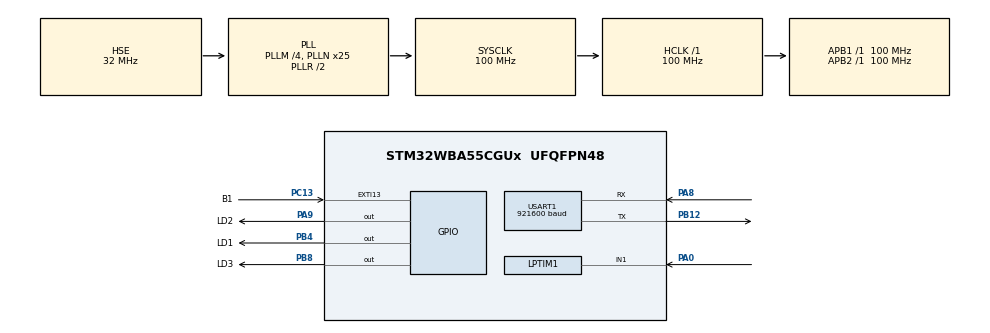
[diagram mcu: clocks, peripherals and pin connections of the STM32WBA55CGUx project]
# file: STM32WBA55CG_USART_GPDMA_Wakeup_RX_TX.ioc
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CORTEX_M33_NS.userName=CORTEX_M33
GPDMA1.CIRCULARMODE_GPDMACH2=ENABLE
GPDMA1.DESTINC_GPDMACH2=DMA_DINC_INCREMENTED
GPDMA1.DIRECTION_GPDMACH3=DMA_MEMORY_TO_PERIPH
GPDMA1.IPHANDLE_GPDMACH2-SIMPLEREQUEST_GPDMACH2=__NULL
GPDMA1.IPHANDLE_GPDMACH3-SIMPLEREQUEST_GPDMACH3=__NULL
GPDMA1.PRIORITY_GPDMACH3=DMA_LOW_PRIORITY_HIGH_WEIGHT
GPDMA1.REQUEST_GPDMACH2=GPDMA1_REQUEST_USART1_RX
GPDMA1.REQUEST_GPDMACH3=GPDMA1_REQUEST_USART1_TX
GPDMA1.SRCINC_GPDMACH3=DMA_SINC_INCREMENTED
LPTIM1.Period=1000
LPTIM1.TriggerSource=LPTIM_TRIGSOURCE_SOFTWARE
LPTIM1.ULPClockPolarity=LPTIM_CLOCKPOLARITY_RISING
LPTIM1.ULPClockSampleTime=LPTIM_CLOCKSAMPLETIME_DIRECTTRANSITION
LPTIM1.UpdateMode=LPTIM_UPDATE_IMMEDIATE
Mcu.Family=STM32WBA
Mcu.Name=STM32WBA55CGUx
Mcu.Package=UFQFPN48
NVIC.EXTI13_IRQn=true\:0\:0\:false\:false\:true\:true\:true\:true
NVIC.GPDMA1_Channel2_IRQn=true\:0\:0\:false\:false\:true\:false\:true\:true
NVIC.GPDMA1_Channel3_IRQn=true\:0\:0\:false\:false\:true\:false\:true\:true
NVIC.LPTIM1_IRQn=true\:0\:0\:false\:false\:true\:true\:true\:true
NVIC.PriorityGroup=NVIC_PRIORITYGROUP_4
OSC_IN.Mode=HSE-External-Oscillator
OSC_IN.Signal=RCC_OSC_IN
OSC_OUT.Mode=HSE-External-Oscillator
OSC_OUT.Signal=RCC_OSC_OUT
PA0.Mode=Counts_external_clock_with_synchro_01_occur1
PA0.Signal=LPTIM1_IN1
PA8.Mode=Asynchronous
PA8.Signal=USART1_RX
PA9.GPIO_Label=LD2
PA9.Signal=GPIO_Output
PB12.Mode=Asynchronous
PB12.Signal=USART1_TX
PB4\ (NJTRST).GPIO_Label=LD1
PB4\ (NJTRST).Signal=GPIO_Output
PB8.GPIO_Label=LD3
PB8.Signal=GPIO_Output
PC13.GPIO_Label=B1
PC13.GPIO_ModeDefaultEXTI=GPIO_MODE_IT_FALLING
PC13.GPIO_PuPd=GPIO_PULLUP
PC13.Signal=GPXTI13
ProjectManager.HeapSize=0x200
ProjectManager.StackSize=0x400
ProjectManager.TargetToolchain=STM32CubeIDE
RCC.ADCFreq_Value=100000000
RCC.AHB5CLKDivider=DIV4
RCC.AHBFreq_Value=100000000
RCC.APB1Freq_Value=100000000
RCC.APB1TimFreq_Value=100000000
RCC.APB2Freq_Value=100000000
RCC.APB2TimFreq_Value=100000000
RCC.CortexFreq_Value=12500000
RCC.HCLKFreq_Value=100000000
RCC.HSE_VALUE=32000000
RCC.HSI_VALUE=16000000
RCC.LPTIM1CLockSelectionVirtual=RCC_LPTIM1CLKSOURCE_LSI
RCC.LSE_VALUE=32768
RCC.LSI1_VALUE=32000
RCC.LSI2_VALUE=32000
RCC.PLLFRACN=0
RCC.PLLM=4
RCC.PLLN=25
RCC.PLLSourceVirtual=RCC_PLLSOURCE_HSE
RCC.SYSCLKFreq_VALUE=100000000
RCC.SYSCLKSourceVirtual=RCC_SYSCLKSOURCE_PLLCLK
RCC.SupplySource=PWR_SMPS_SUPPLY
RCC.USART1CLockSelectionVirtual=RCC_USART1CLKSOURCE_HSI
RCC.VCOOutputFreq_Value=200000000
USART1.AutonomousMode=AUTONOMOUS_MODE_ENABLE
USART1.BaudRate=921600
USART1.DataSize=10
USART1.IdleFrame=UART_IDLE_FRAME_ENABLE
USART1.TriggerSelection=UART_LPTIM1_OUT_TRG
USART1.VirtualMode-Asynchronous=VM_ASYNC
VP_CORTEX_M33_NS_VS_Hclk.Mode=Hclk_Mode
VP_GPDMA1_VS_GPDMACH2.Mode=SIMPLEREQUEST_GPDMACH2
VP_GPDMA1_VS_GPDMACH3.Mode=SIMPLEREQUEST_GPDMACH3
VP_ICACHE_VS_ICACHE.Mode=DirectMappedCache
VP_MEMORYMAP_VS_MEMORYMAP.Mode=CurAppReg
VP_PWR_VS_SECSignals.Mode=Security/Privilege
board=custom

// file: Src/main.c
/* USER CODE BEGIN Header */
/**
  ******************************************************************************
  * @file    LPTIM/LPTIM_PulseCounter/Src/main.c
  * @author  MCD Application Team
  * @brief   This example describes how to configure and use the LPTIM in counter
  *          mode through the STM32WBAxx HAL API.
  ******************************************************************************
  * @attention
  *
  * Copyright (c) 2022 STMicroelectronics.
  * All rights reserved.
  *
  * This software is licensed under terms that can be found in the LICENSE file
  * in the root directory of this software component.
  * If no LICENSE file comes with this software, it is provided AS-IS.
  *
  ******************************************************************************
  */
/* USER CODE END Header */
#include "main.h"

LPTIM_HandleTypeDef hlptim1;

UART_HandleTypeDef huart1;
DMA_HandleTypeDef handle_GPDMA1_Channel3;
DMA_NodeTypeDef Node_GPDMA1_Channel2;
DMA_QListTypeDef List_GPDMA1_Channel2;
DMA_HandleTypeDef handle_GPDMA1_Channel2;

void SystemClock_Config(void);
static void MX_GPIO_Init(void);
static void MX_GPDMA1_Init(void);
static void MX_ICACHE_Init(void);
static void MX_USART1_UART_Init(void);
static void MX_LPTIM1_Init(void);

int main(void)
{

  /* USER CODE BEGIN 1 */
  /* STM32WBAxx HAL library initialization:
       - Systick timer is configured by default as source of time base, but user
             can eventually implement his proper time base source (a general purpose
             timer for example or other time source), keeping in mind that Time base
             duration should be kept 1ms since PPP_TIMEOUT_VALUEs are defined and
             handled in milliseconds basis.
       - Set NVIC Group Priority to 4
       - Low Level Initialization
     */

  /* USER CODE END 1 */

  /* MCU Configuration--------------------------------------------------------*/

  /* Reset of all peripherals, Initializes the Flash interface and the Systick. */
  HAL_Init();

  /* Configure the system clock */
  SystemClock_Config();

  /* Initialize all configured peripherals */
  MX_GPIO_Init();
  MX_GPDMA1_Init();
  MX_ICACHE_Init();
  MX_USART1_UART_Init();
  MX_LPTIM1_Init();
  /* USER CODE BEGIN 2 */

  /* ### Start counting in interrupt mode ############################# */
  /*
   *  Period = 1000
   */
  if (HAL_LPTIM_Counter_Start_IT(&hlptim1) != HAL_OK)
  {
    Error_Handler();
  }

  /* Disable autoreload write complete interrupt */
  __HAL_LPTIM_DISABLE_IT(&hlptim1, LPTIM_IT_ARROK);

  /* ### Enter in Stop mode ########################################### */
  HAL_PWR_EnterSTOPMode(PWR_LOWPOWERREGULATOR_ON, PWR_STOPENTRY_WFI);

  /* USER CODE END 2 */

  /* Infinite loop */
  while (1)
  {

  }
}

void SystemClock_Config(void)
{
  RCC_OscInitTypeDef RCC_OscInitStruct = {0};
  RCC_ClkInitTypeDef RCC_ClkInitStruct = {0};

  /** Supply configuration update enable
  */
  HAL_PWREx_ConfigSupply(PWR_SMPS_SUPPLY);

  /** Configure the main internal regulator output voltage
  */
  if (HAL_PWREx_ControlVoltageScaling(PWR_REGULATOR_VOLTAGE_SCALE1) != HAL_OK)
  {
    Error_Handler();
  }

  /** Initializes the CPU, AHB and APB busses clocks
  */
  RCC_OscInitStruct.OscillatorType = RCC_OSCILLATORTYPE_HSI|RCC_OSCILLATORTYPE_LSI
                              |RCC_OSCILLATORTYPE_HSE;
  RCC_OscInitStruct.HSEState = RCC_HSE_ON;
  RCC_OscInitStruct.HSEDiv = RCC_HSE_DIV1;
  RCC_OscInitStruct.HSIState = RCC_HSI_ON;
  RCC_OscInitStruct.HSICalibrationValue = RCC_HSICALIBRATION_DEFAULT;
  RCC_OscInitStruct.LSIState = RCC_LSI1_ON;
  RCC_OscInitStruct.LSIDiv = RCC_LSI_DIV1;
  RCC_OscInitStruct.PLL1.PLLState = RCC_PLL_ON;
  RCC_OscInitStruct.PLL1.PLLSource = RCC_PLLSOURCE_HSE;
  RCC_OscInitStruct.PLL1.PLLM = 4;
  RCC_OscInitStruct.PLL1.PLLN = 25;
  RCC_OscInitStruct.PLL1.PLLP = 2;
  RCC_OscInitStruct.PLL1.PLLQ = 2;
  RCC_OscInitStruct.PLL1.PLLR = 2;
  RCC_OscInitStruct.PLL1.PLLFractional = 0;
  if (HAL_RCC_OscConfig(&RCC_OscInitStruct) != HAL_OK)
  {
    Error_Handler();
  }

  /** Initializes the CPU, AHB and APB busses clocks
  */
  RCC_ClkInitStruct.ClockType = RCC_CLOCKTYPE_HCLK|RCC_CLOCKTYPE_SYSCLK
                              |RCC_CLOCKTYPE_PCLK1|RCC_CLOCKTYPE_PCLK2
                              |RCC_CLOCKTYPE_PCLK7|RCC_CLOCKTYPE_HCLK5;
  RCC_ClkInitStruct.SYSCLKSource = RCC_SYSCLKSOURCE_PLLCLK;
  RCC_ClkInitStruct.AHBCLKDivider = RCC_SYSCLK_DIV1;
  RCC_ClkInitStruct.APB1CLKDivider = RCC_HCLK_DIV1;
  RCC_ClkInitStruct.APB2CLKDivider = RCC_HCLK_DIV1;
  RCC_ClkInitStruct.APB7CLKDivider = RCC_HCLK_DIV1;
  RCC_ClkInitStruct.AHB5_PLL1_CLKDivider = RCC_SYSCLK_PLL1_DIV4;
  RCC_ClkInitStruct.AHB5_HSEHSI_CLKDivider = RCC_SYSCLK_HSEHSI_DIV1;

  if (HAL_RCC_ClockConfig(&RCC_ClkInitStruct, FLASH_LATENCY_3) != HAL_OK)
  {
    Error_Handler();
  }
}

static void MX_GPDMA1_Init(void)
{

  /* Peripheral clock enable */
  __HAL_RCC_GPDMA1_CLK_ENABLE();

  /* GPDMA1 interrupt Init */
    HAL_NVIC_SetPriority(GPDMA1_Channel2_IRQn, 0, 0);
    HAL_NVIC_EnableIRQ(GPDMA1_Channel2_IRQn);
    HAL_NVIC_SetPriority(GPDMA1_Channel3_IRQn, 0, 0);
    HAL_NVIC_EnableIRQ(GPDMA1_Channel3_IRQn);

}

static void MX_ICACHE_Init(void)
{

  /** Enable instruction cache in 1-way (direct mapped cache)
  */
  if (HAL_ICACHE_ConfigAssociativityMode(ICACHE_1WAY) != HAL_OK)
  {
    Error_Handler();
  }
  if (HAL_ICACHE_Enable() != HAL_OK)
  {
    Error_Handler();
  }

}

static void MX_LPTIM1_Init(void)
{

  hlptim1.Instance = LPTIM1;
  hlptim1.Init.Clock.Source = LPTIM_CLOCKSOURCE_APBCLOCK_LPOSC;
  hlptim1.Init.Clock.Prescaler = LPTIM_PRESCALER_DIV1;
  hlptim1.Init.UltraLowPowerClock.Polarity = LPTIM_CLOCKPOLARITY_RISING;
  hlptim1.Init.UltraLowPowerClock.SampleTime = LPTIM_CLOCKSAMPLETIME_DIRECTTRANSITION;
  hlptim1.Init.Trigger.Source = LPTIM_TRIGSOURCE_SOFTWARE;
  hlptim1.Init.Period = 1000;
  hlptim1.Init.UpdateMode = LPTIM_UPDATE_IMMEDIATE;
  hlptim1.Init.CounterSource = LPTIM_COUNTERSOURCE_EXTERNAL;
  hlptim1.Init.Input1Source = LPTIM_INPUT1SOURCE_GPIO;
  hlptim1.Init.Input2Source = LPTIM_INPUT2SOURCE_GPIO;
  hlptim1.Init.RepetitionCounter = 0;
  if (HAL_LPTIM_Init(&hlptim1) != HAL_OK)
  {
    Error_Handler();
  }

}

static void MX_USART1_UART_Init(void)
{

  UART_AutonomousModeConfTypeDef sConfigUart1 = {0};

  huart1.Instance = USART1;
  huart1.Init.BaudRate = 921600;
  huart1.Init.WordLength = UART_WORDLENGTH_8B;
  huart1.Init.StopBits = UART_STOPBITS_1;
  huart1.Init.Parity = UART_PARITY_NONE;
  huart1.Init.Mode = UART_MODE_TX_RX;
  huart1.Init.HwFlowCtl = UART_HWCONTROL_NONE;
  huart1.Init.OverSampling = UART_OVERSAMPLING_16;
  huart1.Init.OneBitSampling = UART_ONE_BIT_SAMPLE_DISABLE;
  huart1.Init.ClockPrescaler = UART_PRESCALER_DIV1;
  huart1.AdvancedInit.AdvFeatureInit = UART_ADVFEATURE_NO_INIT;
  if (HAL_UART_Init(&huart1) != HAL_OK)
  {
    Error_Handler();
  }
  if (HAL_UARTEx_SetTxFifoThreshold(&huart1, UART_TXFIFO_THRESHOLD_1_8) != HAL_OK)
  {
    Error_Handler();
  }
  if (HAL_UARTEx_SetRxFifoThreshold(&huart1, UART_RXFIFO_THRESHOLD_1_8) != HAL_OK)
  {
    Error_Handler();
  }
  if (HAL_UARTEx_DisableFifoMode(&huart1) != HAL_OK)
  {
    Error_Handler();
  }
  sConfigUart1.AutonomousModeState = UART_AUTONOMOUS_MODE_ENABLE;
  sConfigUart1.TriggerSelection = UART_LPTIM1_OUT_TRG;
  sConfigUart1.TriggerPolarity = UART_TRIG_POLARITY_RISING;
  sConfigUart1.DataSize = 10;
  sConfigUart1.IdleFrame = UART_IDLE_FRAME_ENABLE;
  if (HAL_UARTEx_SetConfigAutonomousMode(&huart1, &sConfigUart1) != HAL_OK)
  {
    Error_Handler();
  }

}

static void MX_GPIO_Init(void)
{
  GPIO_InitTypeDef GPIO_InitStruct = {0};

  /* GPIO Ports Clock Enable */
  __HAL_RCC_GPIOB_CLK_ENABLE();
  __HAL_RCC_GPIOA_CLK_ENABLE();
  __HAL_RCC_GPIOC_CLK_ENABLE();

  /*Configure GPIO pin Output Level */
  HAL_GPIO_WritePin(GPIOB, LD3_Pin|LD1_Pin, GPIO_PIN_SET);

  /*Configure GPIO pin Output Level */
  HAL_GPIO_WritePin(LD2_GPIO_Port, LD2_Pin, GPIO_PIN_SET);

  /*Configure GPIO pins : LD3_Pin LD1_Pin */
  GPIO_InitStruct.Pin = LD3_Pin|LD1_Pin;
  GPIO_InitStruct.Mode = GPIO_MODE_OUTPUT_PP;
  GPIO_InitStruct.Pull = GPIO_NOPULL;
  GPIO_InitStruct.Speed = GPIO_SPEED_FREQ_LOW;
  HAL_GPIO_Init(GPIOB, &GPIO_InitStruct);

  /*Configure GPIO pin : B1_Pin */
  GPIO_InitStruct.Pin = B1_Pin;
  GPIO_InitStruct.Mode = GPIO_MODE_IT_FALLING;
  GPIO_InitStruct.Pull = GPIO_PULLUP;
  HAL_GPIO_Init(B1_GPIO_Port, &GPIO_InitStruct);

  /*Configure GPIO pin : LD2_Pin */
  GPIO_InitStruct.Pin = LD2_Pin;
  GPIO_InitStruct.Mode = GPIO_MODE_OUTPUT_PP;
  GPIO_InitStruct.Pull = GPIO_NOPULL;
  GPIO_InitStruct.Speed = GPIO_SPEED_FREQ_LOW;
  HAL_GPIO_Init(LD2_GPIO_Port, &GPIO_InitStruct);

  /* EXTI interrupt init*/
  HAL_NVIC_SetPriority(EXTI13_IRQn, 0, 0);
  HAL_NVIC_EnableIRQ(EXTI13_IRQn);

}

/* USER CODE BEGIN 4 */

/**
  * @brief  Autoreload match callback in non blocking mode
  * @param  hlptim : LPTIM handle
  * @retval None
  */
void HAL_LPTIM_AutoReloadMatchCallback(LPTIM_HandleTypeDef *hlptim)
{
  /* Turn on LD1 */
  HAL_GPIO_TogglePin(LD1_GPIO_Port, LD1_Pin);
}

/* USER CODE END 4 */

void Error_Handler(void)
{
  /* USER CODE BEGIN Error_Handler_Debug */
  /* Turn LD3 on */
  HAL_GPIO_WritePin(LD3_GPIO_Port, LD3_Pin, GPIO_PIN_RESET);
  while(1)
  {
  }
  /* USER CODE END Error_Handler_Debug */
}
